AUTOSAR XML (schema 4-2-1)
package /ComponentTypes
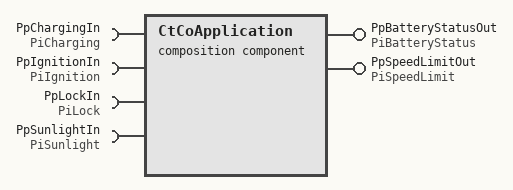
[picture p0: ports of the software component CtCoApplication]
  composition sw component type CtCoApplication
    provide port PpBatteryStatusOut: nonqueued-sender-com-spec=data-element=DeBatteryStatus, provided-interface=PiBatteryStatus
    provide port PpSpeedLimitOut: nonqueued-sender-com-spec=data-element=DeSpeedLimit, provided-interface=PiSpeedLimit
    4 x require port:
      PpChargingIn: nonqueued-receiver-com-spec{data-element=DeCharging, filter=data-filter-type=ALWAYS}, required-interface=PiCharging
      PpIgnitionIn: nonqueued-receiver-com-spec{data-element=DeIgnition, filter=data-filter-type=ALWAYS}, required-interface=PiIgnition
      PpLockIn: nonqueued-receiver-com-spec{data-element=DeLock, filter=data-filter-type=ALWAYS}, required-interface=PiLock
      PpSunlightIn: nonqueued-receiver-com-spec{data-element=DeSunlight, filter=data-filter-type=ALWAYS}, required-interface=PiSunlight
    9 x component:
      CpApSEVMIController: type=CtApSEVMIController
      CpSaEngineControl: type=CtSaEngineControl
      CpSaLockControl: type=CtSaLockControl
      CpSaSolarPanelControl: type=CtSaSolarPanelControl
      CpSaSpeedLimit: type=CtSaSpeedLimit
      CpSaSunlightPresence: type=CtSaSunlightPresence
      CtIoHwAb: type=CtIoHwAb
      CtSaBatteryManagement: type=CtSaBatteryManagement
      CtSaBatteryModeManager: type=CtSaBatteryModeManager
    connect CpApSEVMIController.PpSpeedLimit -> CpSaSpeedLimit.PpSpeedLimit
    connect CpApSEVMIController.PpBatteryStatus -> CtSaBatteryManagement.PpBatteryStatus
    connect CpSaEngineControl.PpIgnition -> CpApSEVMIController.PpIgnition
    connect CpSaLockControl.PpLock -> CpApSEVMIController.PpLock
    connect CpSaSolarPanelControl.PpCharging -> CpApSEVMIController.PpCharging
    connect CpSaSunlightPresence.PpSunlight -> CpApSEVMIController.PpSunlight
    connect CtIoHwAb.PpSpeed -> CpApSEVMIController.PpSpeed
    delegate CtSaBatteryManagement.PpBatteryStatusOut <-> outer port PpBatteryStatusOut
    delegate CpSaSolarPanelControl.PpChargingIn <-> outer port PpChargingIn
    delegate CpSaEngineControl.PpIgnitionIn <-> outer port PpIgnitionIn
    delegate CpSaLockControl.PpLockIn <-> outer port PpLockIn
    delegate CpSaSpeedLimit.PpSpeedLimitOut <-> outer port PpSpeedLimitOut
    delegate CpSaSunlightPresence.PpSunlightIn <-> outer port PpSunlightIn
